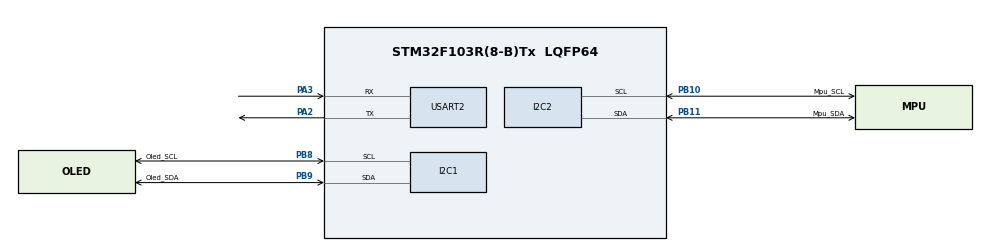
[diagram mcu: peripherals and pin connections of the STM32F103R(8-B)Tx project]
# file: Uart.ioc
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I2C1.I2C_Mode=I2C_Fast
Mcu.Family=STM32F1
Mcu.Name=STM32F103R(8-B)Tx
Mcu.Package=LQFP64
NVIC.PriorityGroup=NVIC_PRIORITYGROUP_4
PA13.Mode=Serial_Wire
PA13.Signal=SYS_JTMS-SWDIO
PA14.Mode=Serial_Wire
PA14.Signal=SYS_JTCK-SWCLK
PA2.Mode=Asynchronous
PA2.Signal=USART2_TX
PA3.Mode=Asynchronous
PA3.Signal=USART2_RX
PB10.GPIO_Label=Mpu_SCL
PB10.Mode=I2C
PB10.Signal=I2C2_SCL
PB11.GPIO_Label=Mpu_SDA
PB11.Mode=I2C
PB11.Signal=I2C2_SDA
PB8.GPIO_Label=Oled_SCL
PB8.Mode=I2C
PB8.Signal=I2C1_SCL
PB9.GPIO_Label=Oled_SDA
PB9.Mode=I2C
PB9.Signal=I2C1_SDA
PD0-OSC_IN.Mode=HSE-External-Oscillator
PD0-OSC_IN.Signal=RCC_OSC_IN
PD1-OSC_OUT.Mode=HSE-External-Oscillator
PD1-OSC_OUT.Signal=RCC_OSC_OUT
ProjectManager.HeapSize=0x200
ProjectManager.StackSize=0x400
ProjectManager.TargetToolchain=STM32CubeIDE
RCC.APB1Freq_Value=8000000
RCC.APB2Freq_Value=8000000
USART2.VirtualMode=VM_ASYNC
board=custom

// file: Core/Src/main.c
/* USER CODE BEGIN Header */
/**
  ******************************************************************************
  * @file           : main.c
  * @brief          : Main program body
  ******************************************************************************
  * @attention
  *
  * Copyright (c) 2023 STMicroelectronics.
  * All rights reserved.
  *
  * This software is licensed under terms that can be found in the LICENSE file
  * in the root directory of this software component.
  * If no LICENSE file comes with this software, it is provided AS-IS.
  *
  ******************************************************************************
  */
/* USER CODE END Header */
#include "main.h"

/* USER CODE BEGIN Includes */
#include "ssd1306.h"
#include "ssd1306_tests.h"
#include "mpu6050.h"
#include <stdlib.h>
#include <stdio.h>
/* USER CODE END Includes */

I2C_HandleTypeDef hi2c1;
I2C_HandleTypeDef hi2c2;
UART_HandleTypeDef huart2;

/* USER CODE BEGIN PV */
MPU6050_typeDef mpu_data;
uint8_t start_frame = 0x24;	//"$"
uint8_t data_frame [6] ;
uint8_t end_frame [2] = {0x0D, 0x0A};//"\r\n"

/* USER CODE END PV */

void SystemClock_Config(void);
static void MX_GPIO_Init(void);
static void MX_I2C1_Init(void);
static void MX_I2C2_Init(void);
static void MX_USART2_UART_Init(void);

int main(void)
{
  /* USER CODE BEGIN 1 */
	char buffer[6];

  /* USER CODE END 1 */

  /* MCU Configuration--------------------------------------------------------*/

  /* Reset of all peripherals, Initializes the Flash interface and the Systick. */
  HAL_Init();

  /* Configure the system clock */
  SystemClock_Config();

  /* Initialize all configured peripherals */
  MX_GPIO_Init();
  MX_I2C1_Init();
  MX_I2C2_Init();
  MX_USART2_UART_Init();

  /* USER CODE BEGIN 2 */
  ssd1306_Init();
  MPU6050_Init(&hi2c2);
  MPU6050_Set_DLPF(&hi2c2, MPU6050_DLPF_6);

  /* USER CODE END 2 */

  /* Infinite loop */
  while (1)
  {
		MPU6050_Read(&hi2c2, &mpu_data);

		data_frame[0] = (uint8_t) mpu_data.Accel_X_RAW;
		data_frame[1] = (uint8_t) (mpu_data.Accel_X_RAW >> 8);
		data_frame[2] = (uint8_t) mpu_data.Accel_Y_RAW;
		data_frame[3] = (uint8_t) (mpu_data.Accel_Y_RAW >> 8);
		data_frame[4] = (uint8_t) mpu_data.Accel_Z_RAW;
		data_frame[5] = (uint8_t) (mpu_data.Accel_Z_RAW >> 8);
		//char data[] = "HELLO WORLD\r\n";
		//HAL_UART_Transmit(&huart2, data, sizeof(data), 10);
		//HAL_UART_Transmit(&huart2, &start_frame, 1, HAL_MAX_DELAY);

		//HAL_UART_Transmit(&huart2, data_frame, 6, HAL_MAX_DELAY);

		//HAL_UART_Transmit(&huart2, end_frame, 2, HAL_MAX_DELAY);

		//HAL_Delay(100);
		//ssd1306_Emlak();
		ssd1306_SetCursor(0,0);
		sprintf(buffer, "AX: %d", mpu_data.Accel_X_RAW);
		ssd1306_WriteString(buffer, Font_7x10, White);
		ssd1306_SetCursor(0,10);
		sprintf(buffer, "AY: %d", mpu_data.Accel_Y_RAW);
		ssd1306_WriteString(buffer, Font_7x10, White);
		ssd1306_SetCursor(0,20);
		sprintf(buffer, "AZ: %d", mpu_data.Accel_Z_RAW);
		ssd1306_WriteString(buffer, Font_7x10, White);
		ssd1306_UpdateScreen();
		HAL_Delay(50);
  }
}

void SystemClock_Config(void)
{
  RCC_OscInitTypeDef RCC_OscInitStruct = {0};
  RCC_ClkInitTypeDef RCC_ClkInitStruct = {0};

  /** Initializes the RCC Oscillators according to the specified parameters
  * in the RCC_OscInitTypeDef structure.
  */
  RCC_OscInitStruct.OscillatorType = RCC_OSCILLATORTYPE_HSI;
  RCC_OscInitStruct.HSIState = RCC_HSI_ON;
  RCC_OscInitStruct.HSICalibrationValue = RCC_HSICALIBRATION_DEFAULT;
  RCC_OscInitStruct.PLL.PLLState = RCC_PLL_NONE;
  if (HAL_RCC_OscConfig(&RCC_OscInitStruct) != HAL_OK)
  {
    Error_Handler();
  }

  /** Initializes the CPU, AHB and APB buses clocks
  */
  RCC_ClkInitStruct.ClockType = RCC_CLOCKTYPE_HCLK|RCC_CLOCKTYPE_SYSCLK
                              |RCC_CLOCKTYPE_PCLK1|RCC_CLOCKTYPE_PCLK2;
  RCC_ClkInitStruct.SYSCLKSource = RCC_SYSCLKSOURCE_HSI;
  RCC_ClkInitStruct.AHBCLKDivider = RCC_SYSCLK_DIV1;
  RCC_ClkInitStruct.APB1CLKDivider = RCC_HCLK_DIV1;
  RCC_ClkInitStruct.APB2CLKDivider = RCC_HCLK_DIV1;

  if (HAL_RCC_ClockConfig(&RCC_ClkInitStruct, FLASH_LATENCY_0) != HAL_OK)
  {
    Error_Handler();
  }
}

static void MX_I2C1_Init(void)
{

  hi2c1.Instance = I2C1;
  hi2c1.Init.ClockSpeed = 400000;
  hi2c1.Init.DutyCycle = I2C_DUTYCYCLE_2;
  hi2c1.Init.OwnAddress1 = 0;
  hi2c1.Init.AddressingMode = I2C_ADDRESSINGMODE_7BIT;
  hi2c1.Init.DualAddressMode = I2C_DUALADDRESS_DISABLE;
  hi2c1.Init.OwnAddress2 = 0;
  hi2c1.Init.GeneralCallMode = I2C_GENERALCALL_DISABLE;
  hi2c1.Init.NoStretchMode = I2C_NOSTRETCH_DISABLE;
  if (HAL_I2C_Init(&hi2c1) != HAL_OK)
  {
    Error_Handler();
  }

}

static void MX_I2C2_Init(void)
{

  hi2c2.Instance = I2C2;
  hi2c2.Init.ClockSpeed = 100000;
  hi2c2.Init.DutyCycle = I2C_DUTYCYCLE_2;
  hi2c2.Init.OwnAddress1 = 0;
  hi2c2.Init.AddressingMode = I2C_ADDRESSINGMODE_7BIT;
  hi2c2.Init.DualAddressMode = I2C_DUALADDRESS_DISABLE;
  hi2c2.Init.OwnAddress2 = 0;
  hi2c2.Init.GeneralCallMode = I2C_GENERALCALL_DISABLE;
  hi2c2.Init.NoStretchMode = I2C_NOSTRETCH_DISABLE;
  if (HAL_I2C_Init(&hi2c2) != HAL_OK)
  {
    Error_Handler();
  }

}

static void MX_USART2_UART_Init(void)
{

  huart2.Instance = USART2;
  huart2.Init.BaudRate = 115200;
  huart2.Init.WordLength = UART_WORDLENGTH_8B;
  huart2.Init.StopBits = UART_STOPBITS_1;
  huart2.Init.Parity = UART_PARITY_NONE;
  huart2.Init.Mode = UART_MODE_TX_RX;
  huart2.Init.HwFlowCtl = UART_HWCONTROL_NONE;
  huart2.Init.OverSampling = UART_OVERSAMPLING_16;
  if (HAL_UART_Init(&huart2) != HAL_OK)
  {
    Error_Handler();
  }

}

static void MX_GPIO_Init(void)
{

  /* GPIO Ports Clock Enable */
  __HAL_RCC_GPIOD_CLK_ENABLE();
  __HAL_RCC_GPIOA_CLK_ENABLE();
  __HAL_RCC_GPIOB_CLK_ENABLE();

}

void Error_Handler(void)
{
  __disable_irq();
  while (1)
  {
  }
}
